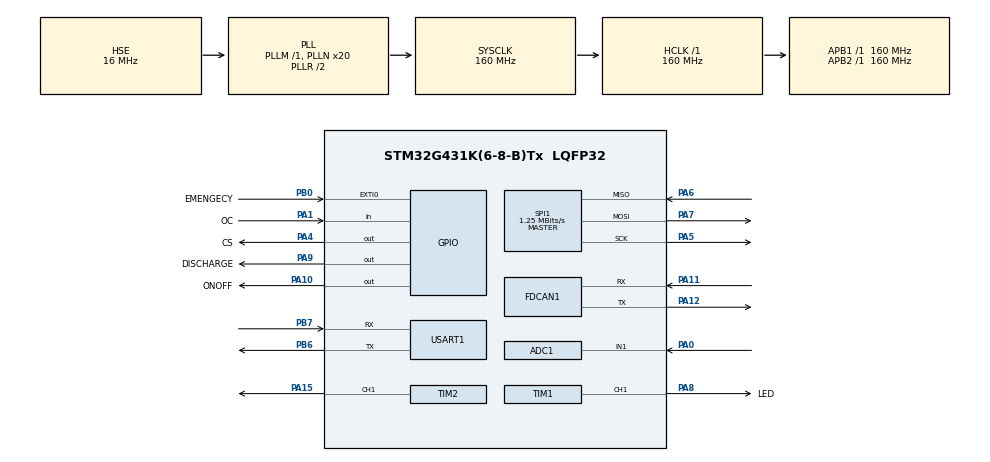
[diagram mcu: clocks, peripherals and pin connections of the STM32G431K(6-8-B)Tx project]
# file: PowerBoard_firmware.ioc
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ADC1.Channel-2\#ChannelRegularConversion=ADC_CHANNEL_1
ADC1.ContinuousConvMode=ENABLE
ADC1.DMAContinuousRequests=ENABLE
ADC1.NbrOfConversionFlag=1
ADC1.OffsetNumber-2\#ChannelRegularConversion=ADC_OFFSET_NONE
ADC1.Rank-2\#ChannelRegularConversion=1
ADC1.SamplingTime-2\#ChannelRegularConversion=ADC_SAMPLETIME_2CYCLES_5
ADC1.master=1
Dma.ADC1.1.Direction=DMA_PERIPH_TO_MEMORY
Dma.ADC1.1.EventEnable=DISABLE
Dma.ADC1.1.Instance=DMA1_Channel1
Dma.ADC1.1.MemDataAlignment=DMA_MDATAALIGN_HALFWORD
Dma.ADC1.1.MemInc=DMA_MINC_ENABLE
Dma.ADC1.1.Mode=DMA_CIRCULAR
Dma.ADC1.1.PeriphDataAlignment=DMA_PDATAALIGN_HALFWORD
Dma.ADC1.1.PeriphInc=DMA_PINC_DISABLE
Dma.ADC1.1.Polarity=HAL_DMAMUX_REQ_GEN_RISING
Dma.ADC1.1.Priority=DMA_PRIORITY_LOW
Dma.ADC1.1.RequestNumber=1
Dma.ADC1.1.SignalID=NONE
Dma.ADC1.1.SyncEnable=DISABLE
Dma.ADC1.1.SyncPolarity=HAL_DMAMUX_SYNC_NO_EVENT
Dma.ADC1.1.SyncRequestNumber=1
Dma.ADC1.1.SyncSignalID=NONE
Dma.Request0=TIM1_CH1
Dma.Request1=ADC1
Dma.Request2=TIM2_CH1
Dma.TIM1_CH1.0.Direction=DMA_MEMORY_TO_PERIPH
Dma.TIM1_CH1.0.EventEnable=DISABLE
Dma.TIM1_CH1.0.Instance=DMA1_Channel3
Dma.TIM1_CH1.0.MemDataAlignment=DMA_MDATAALIGN_WORD
Dma.TIM1_CH1.0.MemInc=DMA_MINC_ENABLE
Dma.TIM1_CH1.0.Mode=DMA_CIRCULAR
Dma.TIM1_CH1.0.PeriphDataAlignment=DMA_PDATAALIGN_HALFWORD
Dma.TIM1_CH1.0.PeriphInc=DMA_PINC_DISABLE
Dma.TIM1_CH1.0.Polarity=HAL_DMAMUX_REQ_GEN_RISING
Dma.TIM1_CH1.0.Priority=DMA_PRIORITY_VERY_HIGH
Dma.TIM1_CH1.0.RequestNumber=1
Dma.TIM1_CH1.0.SignalID=NONE
Dma.TIM1_CH1.0.SyncEnable=DISABLE
Dma.TIM1_CH1.0.SyncPolarity=HAL_DMAMUX_SYNC_NO_EVENT
Dma.TIM1_CH1.0.SyncRequestNumber=1
Dma.TIM1_CH1.0.SyncSignalID=NONE
Dma.TIM2_CH1.2.Direction=DMA_MEMORY_TO_PERIPH
Dma.TIM2_CH1.2.EventEnable=DISABLE
Dma.TIM2_CH1.2.Instance=DMA1_Channel2
Dma.TIM2_CH1.2.MemDataAlignment=DMA_MDATAALIGN_WORD
Dma.TIM2_CH1.2.MemInc=DMA_MINC_ENABLE
Dma.TIM2_CH1.2.Mode=DMA_CIRCULAR
Dma.TIM2_CH1.2.PeriphDataAlignment=DMA_PDATAALIGN_WORD
Dma.TIM2_CH1.2.PeriphInc=DMA_PINC_DISABLE
Dma.TIM2_CH1.2.Polarity=HAL_DMAMUX_REQ_GEN_RISING
Dma.TIM2_CH1.2.Priority=DMA_PRIORITY_VERY_HIGH
Dma.TIM2_CH1.2.RequestNumber=1
Dma.TIM2_CH1.2.SignalID=NONE
Dma.TIM2_CH1.2.SyncEnable=DISABLE
Dma.TIM2_CH1.2.SyncPolarity=HAL_DMAMUX_SYNC_NO_EVENT
Dma.TIM2_CH1.2.SyncRequestNumber=1
Dma.TIM2_CH1.2.SyncSignalID=NONE
FDCAN1.AutoRetransmission=ENABLE
FDCAN1.CalculateBaudRateNominal=1000000
FDCAN1.CalculateTimeBitNominal=1000
FDCAN1.CalculateTimeQuantumNominal=25.0
FDCAN1.DataPrescaler=4
FDCAN1.DataSyncJumpWidth=10
FDCAN1.DataTimeSeg1=9
FDCAN1.DataTimeSeg2=10
FDCAN1.ExtFiltersNbr=0
FDCAN1.FrameFormat=FDCAN_FRAME_FD_BRS
FDCAN1.NominalPrescaler=4
FDCAN1.NominalSyncJumpWidth=10
FDCAN1.NominalTimeSeg1=29
FDCAN1.NominalTimeSeg2=10
FDCAN1.ProtocolException=ENABLE
FDCAN1.StdFiltersNbr=2
FDCAN1.TransmitPause=DISABLE
FREERTOS.Tasks01=defaultTask,24,512,StartDefaultTask,As weak,NULL,Static,defaultTaskBuffer,defaultTaskControlBlock;LEDTask,24,512,controllLEDTask,As weak,NULL,Static,controllLEDTaskBuffer,controllLEDTaskControlBlock
FREERTOS.Timers01=dischargeTimer,dischargeCallback,osTimerOnce,As weak,NULL,Dynamic,NULL;cantx_task,cantxCallback,osTimerPeriodic,As weak,NULL,Dynamic,NULL
Mcu.Family=STM32G4
Mcu.Name=STM32G431K(6-8-B)Tx
Mcu.Package=LQFP32
NVIC.DMA1_Channel1_IRQn=true\:5\:0\:false\:false\:true\:true\:false\:true\:true
NVIC.DMA1_Channel2_IRQn=true\:5\:0\:false\:false\:true\:true\:false\:true\:true
NVIC.DMA1_Channel3_IRQn=true\:5\:0\:false\:false\:true\:true\:false\:true\:true
NVIC.EXTI0_IRQn=true\:5\:0\:false\:false\:true\:true\:true\:true\:true
NVIC.FDCAN1_IT0_IRQn=true\:5\:0\:false\:false\:true\:true\:true\:true\:true
NVIC.FDCAN1_IT1_IRQn=true\:5\:0\:false\:false\:true\:true\:true\:true\:true
NVIC.PriorityGroup=NVIC_PRIORITYGROUP_4
NVIC.TIM6_DAC_IRQn=true\:15\:0\:false\:false\:true\:false\:false\:true\:true
NVIC.TimeBase=TIM6_DAC_IRQn
NVIC.TimeBaseIP=TIM6
PA0.Mode=IN1-Single-Ended
PA0.Signal=ADC1_IN1
PA1.GPIO_Label=OC
PA1.Signal=GPIO_Input
PA10.GPIO_Label=ONOFF
PA10.Signal=GPIO_Output
PA11.GPIO_Speed=GPIO_SPEED_FREQ_HIGH
PA11.Mode=FDCAN_Activate
PA11.Signal=FDCAN1_RX
PA12.GPIO_Speed=GPIO_SPEED_FREQ_HIGH
PA12.Mode=FDCAN_Activate
PA12.Signal=FDCAN1_TX
PA13.Mode=Trace_Asynchronous_SW
PA13.Signal=SYS_JTMS-SWDIO
PA14.Mode=Trace_Asynchronous_SW
PA14.Signal=SYS_JTCK-SWCLK
PA15.Signal=S_TIM2_CH1
PA4.GPIO_Label=CS
PA4.Signal=GPIO_Output
PA5.Mode=Full_Duplex_Master
PA5.Signal=SPI1_SCK
PA6.Mode=Full_Duplex_Master
PA6.Signal=SPI1_MISO
PA7.Mode=Full_Duplex_Master
PA7.Signal=SPI1_MOSI
PA8.GPIO_Label=LED
PA8.Signal=S_TIM1_CH1
PA9.GPIO_Label=DISCHARGE
PA9.Signal=GPIO_Output
PB0.GPIO_Label=EMENGECY
PB0.GPIO_ModeDefaultEXTI=GPIO_MODE_IT_RISING_FALLING
PB0.Signal=GPXTI0
PB3.Mode=Trace_Asynchronous_SW
PB3.Signal=SYS_JTDO-SWO
PB6.Mode=Asynchronous
PB6.Signal=USART1_TX
PB7.Mode=Asynchronous
PB7.Signal=USART1_RX
PF0-OSC_IN.Mode=HSE-External-Oscillator
PF0-OSC_IN.Signal=RCC_OSC_IN
PF1-OSC_OUT.Mode=HSE-External-Oscillator
PF1-OSC_OUT.Signal=RCC_OSC_OUT
ProjectManager.HeapSize=0x200
ProjectManager.StackSize=0x400
ProjectManager.TargetToolchain=CMake
RCC.ADC12Freq_Value=160000000
RCC.AHBFreq_Value=160000000
RCC.APB1Freq_Value=160000000
RCC.APB1TimFreq_Value=160000000
RCC.APB2Freq_Value=160000000
RCC.APB2TimFreq_Value=160000000
RCC.CortexFreq_Value=160000000
RCC.EXTERNAL_CLOCK_VALUE=12288000
RCC.HCLKFreq_Value=160000000
RCC.HSE_VALUE=16000000
RCC.HSI48_VALUE=48000000
RCC.HSI_VALUE=16000000
RCC.LSE_VALUE=32768
RCC.PLLN=20
RCC.PLLSourceVirtual=RCC_PLLSOURCE_HSE
RCC.SYSCLKFreq_VALUE=160000000
RCC.SYSCLKSource=RCC_SYSCLKSOURCE_PLLCLK
RCC.USBFreq_Value=160000000
RCC.VCOOutputFreq_Value=320000000
SH.S_TIM1_CH1.0=TIM1_CH1,PWM Generation1 CH1
SH.S_TIM2_CH1.0=TIM2_CH1,PWM Generation1 CH1
SPI1.BaudRatePrescaler=SPI_BAUDRATEPRESCALER_128
SPI1.CalculateBaudRate=1.25 MBits/s
SPI1.DataSize=SPI_DATASIZE_8BIT
SPI1.Direction=SPI_DIRECTION_2LINES
SPI1.Mode=SPI_MODE_MASTER
SPI1.VirtualType=VM_MASTER
TIM1.Channel-PWM\ Generation1\ CH1=TIM_CHANNEL_1
TIM1.OCFastMode_PWM-PWM\ Generation1\ CH1=TIM_OCFAST_ENABLE
TIM1.PeriodNoDither=19
TIM1.Prescaler=9
TIM2.Channel-PWM\ Generation1\ CH1=TIM_CHANNEL_1
TIM2.OCFastMode_PWM-PWM\ Generation1\ CH1=TIM_OCFAST_ENABLE
TIM2.PeriodNoDither=19
TIM2.Prescaler=9
USART1.VirtualMode-Asynchronous=VM_ASYNC
VP_FREERTOS_VS_CMSIS_V2.Mode=CMSIS_V2
VP_SYS_VS_DBSignals.Mode=DisableDeadBatterySignals
VP_SYS_VS_tim6.Mode=TIM6
board=custom

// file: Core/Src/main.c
/* USER CODE BEGIN Header */
/**
 ******************************************************************************
 * @file           : main.c
 * @brief          : Main program body
 ******************************************************************************
 * @attention
 *
 * Copyright (c) 2025 STMicroelectronics.
 * All rights reserved.
 *
 * This software is licensed under terms that can be found in the LICENSE file
 * in the root directory of this software component.
 * If no LICENSE file comes with this software, it is provided AS-IS.
 *
 ******************************************************************************
 */
/* USER CODE END Header */
#include "main.h"
#include "cmsis_os.h"
#include "adc.h"
#include "dma.h"
#include "fdcan.h"
#include "spi.h"
#include "tim.h"
#include "usart.h"
#include "gpio.h"

/* USER CODE BEGIN Includes */
#include <stdio.h>
/* USER CODE END Includes */

void SystemClock_Config(void);
void MX_FREERTOS_Init(void);

/* USER CODE BEGIN 0 */
int _write(int file, char *ptr, int len)
{
  HAL_UART_Transmit(&huart1, (uint8_t *)ptr, len, 10);
  return len;
}

/* USER CODE END 0 */

int main(void)
{

  /* MCU Configuration--------------------------------------------------------*/

  /* Reset of all peripherals, Initializes the Flash interface and the Systick. */
  HAL_Init();

  /* USER CODE BEGIN Init */
  setbuf(stdout, NULL);
  /* USER CODE END Init */

  /* Configure the system clock */
  SystemClock_Config();

  /* Initialize all configured peripherals */
  MX_GPIO_Init();
  MX_DMA_Init();
  MX_FDCAN1_Init();
  MX_ADC1_Init();
  MX_TIM1_Init();
  MX_USART1_UART_Init();
  MX_SPI1_Init();
  MX_TIM2_Init();

  /* Init scheduler */
  osKernelInitialize();

  /* Call init function for freertos objects (in cmsis_os2.c) */
  MX_FREERTOS_Init();

  /* Start scheduler */
  osKernelStart();

  /* We should never get here as control is now taken by the scheduler */

  /* Infinite loop */
  while (1)
  {

  }
}

void SystemClock_Config(void)
{
  RCC_OscInitTypeDef RCC_OscInitStruct = {0};
  RCC_ClkInitTypeDef RCC_ClkInitStruct = {0};

  /** Configure the main internal regulator output voltage
   */
  HAL_PWREx_ControlVoltageScaling(PWR_REGULATOR_VOLTAGE_SCALE1_BOOST);

  /** Initializes the RCC Oscillators according to the specified parameters
   * in the RCC_OscInitTypeDef structure.
   */
  RCC_OscInitStruct.OscillatorType = RCC_OSCILLATORTYPE_HSE;
  RCC_OscInitStruct.HSEState = RCC_HSE_ON;
  RCC_OscInitStruct.PLL.PLLState = RCC_PLL_ON;
  RCC_OscInitStruct.PLL.PLLSource = RCC_PLLSOURCE_HSE;
  RCC_OscInitStruct.PLL.PLLM = RCC_PLLM_DIV1;
  RCC_OscInitStruct.PLL.PLLN = 20;
  RCC_OscInitStruct.PLL.PLLP = RCC_PLLP_DIV2;
  RCC_OscInitStruct.PLL.PLLQ = RCC_PLLQ_DIV2;
  RCC_OscInitStruct.PLL.PLLR = RCC_PLLR_DIV2;
  if (HAL_RCC_OscConfig(&RCC_OscInitStruct) != HAL_OK)
  {
    Error_Handler();
  }

  /** Initializes the CPU, AHB and APB buses clocks
   */
  RCC_ClkInitStruct.ClockType = RCC_CLOCKTYPE_HCLK | RCC_CLOCKTYPE_SYSCLK | RCC_CLOCKTYPE_PCLK1 | RCC_CLOCKTYPE_PCLK2;
  RCC_ClkInitStruct.SYSCLKSource = RCC_SYSCLKSOURCE_PLLCLK;
  RCC_ClkInitStruct.AHBCLKDivider = RCC_SYSCLK_DIV1;
  RCC_ClkInitStruct.APB1CLKDivider = RCC_HCLK_DIV1;
  RCC_ClkInitStruct.APB2CLKDivider = RCC_HCLK_DIV1;

  if (HAL_RCC_ClockConfig(&RCC_ClkInitStruct, FLASH_LATENCY_4) != HAL_OK)
  {
    Error_Handler();
  }
}

void HAL_TIM_PeriodElapsedCallback(TIM_HandleTypeDef *htim)
{
  if (htim->Instance == TIM6)
  {
    HAL_IncTick();
  }
}

void Error_Handler(void)
{
  __disable_irq();
  while (1)
  {
  }
}

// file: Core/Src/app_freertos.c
/* USER CODE BEGIN Header */
/**
  ******************************************************************************
  * File Name          : app_freertos.c
  * Description        : Code for freertos applications
  ******************************************************************************
  * @attention
  *
  * Copyright (c) 2025 STMicroelectronics.
  * All rights reserved.
  *
  * This software is licensed under terms that can be found in the LICENSE file
  * in the root directory of this software component.
  * If no LICENSE file comes with this software, it is provided AS-IS.
  *
  ******************************************************************************
  */
/* USER CODE END Header */

#include "FreeRTOS.h"
#include "task.h"
#include "main.h"
#include "cmsis_os.h"

typedef StaticTask_t osStaticThreadDef_t;

/* Definitions for defaultTask */
osThreadId_t defaultTaskHandle;
uint32_t defaultTaskBuffer[ 512 ];
osStaticThreadDef_t defaultTaskControlBlock;
const osThreadAttr_t defaultTask_attributes = {
  .name = "defaultTask",
  .stack_mem = &defaultTaskBuffer[0],
  .stack_size = sizeof(defaultTaskBuffer),
  .cb_mem = &defaultTaskControlBlock,
  .cb_size = sizeof(defaultTaskControlBlock),
  .priority = (osPriority_t) osPriorityNormal,
};
/* Definitions for LEDTask */
osThreadId_t LEDTaskHandle;
uint32_t controllLEDTaskBuffer[ 512 ];
osStaticThreadDef_t controllLEDTaskControlBlock;
const osThreadAttr_t LEDTask_attributes = {
  .name = "LEDTask",
  .stack_mem = &controllLEDTaskBuffer[0],
  .stack_size = sizeof(controllLEDTaskBuffer),
  .cb_mem = &controllLEDTaskControlBlock,
  .cb_size = sizeof(controllLEDTaskControlBlock),
  .priority = (osPriority_t) osPriorityNormal,
};
/* Definitions for dischargeTimer */
osTimerId_t dischargeTimerHandle;
const osTimerAttr_t dischargeTimer_attributes = {
  .name = "dischargeTimer"
};
/* Definitions for cantx_task */
osTimerId_t cantx_taskHandle;
const osTimerAttr_t cantx_task_attributes = {
  .name = "cantx_task"
};

void StartDefaultTask(void *argument);
void controllLEDTask(void *argument);
void dischargeCallback(void *argument);
void cantxCallback(void *argument);

void MX_FREERTOS_Init(void); /* (MISRA C 2004 rule 8.1) */

void MX_FREERTOS_Init(void) {

  /* Create the timer(s) */
  /* creation of dischargeTimer */
  dischargeTimerHandle = osTimerNew(dischargeCallback, osTimerOnce, NULL, &dischargeTimer_attributes);

  /* creation of cantx_task */
  cantx_taskHandle = osTimerNew(cantxCallback, osTimerPeriodic, NULL, &cantx_task_attributes);

  /* Create the thread(s) */
  /* creation of defaultTask */
  defaultTaskHandle = osThreadNew(StartDefaultTask, NULL, &defaultTask_attributes);

  /* creation of LEDTask */
  LEDTaskHandle = osThreadNew(controllLEDTask, NULL, &LEDTask_attributes);

}

__weak void StartDefaultTask(void *argument)
{
  for(;;)
  {
    osDelay(1);
  }
}

__weak void controllLEDTask(void *argument)
{
  for(;;)
  {
    osDelay(1);
  }
}

/* dischargeCallback function */
__weak void dischargeCallback(void *argument)
{
}

/* cantxCallback function */
__weak void cantxCallback(void *argument)
{
}
